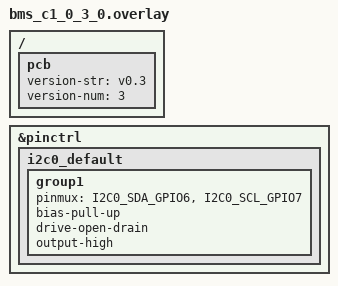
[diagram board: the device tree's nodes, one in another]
/*
 * Copyright (c) The Libre Solar Project Contributors
 *
 * SPDX-License-Identifier: Apache-2.0
 */

/ {
	pcb {
		version-str = "v0.3";
		version-num = <3>;
	};
};

&pinctrl {
	i2c0_default: i2c0_default {
		group1 {
			pinmux = <I2C0_SDA_GPIO6>,
				 <I2C0_SCL_GPIO7>;
			bias-pull-up;
			drive-open-drain;
			output-high;
		};
	};
};
